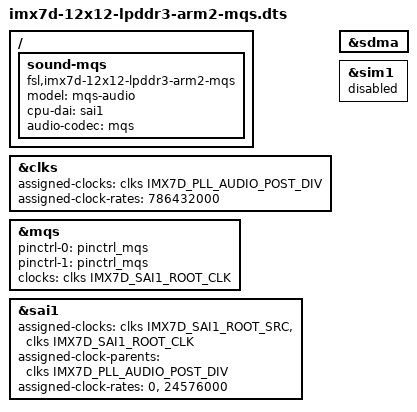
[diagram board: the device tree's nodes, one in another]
/*
 * Copyright (C) 2015 Freescale Semiconductor, Inc.
 *
 * This program is free software; you can redistribute it and/or modify
 * it under the terms of the GNU General Public License version 2 as
 * published by the Free Software Foundation.
 */

#include "imx7d-12x12-lpddr3-arm2.dts"

/ {
	sound-mqs {
		compatible = "fsl,imx7d-12x12-lpddr3-arm2-mqs",
				"fsl,imx-audio-mqs";
		model = "mqs-audio";
		cpu-dai = <&sai1>;
		audio-codec = <&mqs>;
	};
};

&clks {
	assigned-clocks = <&clks IMX7D_PLL_AUDIO_POST_DIV>;
	assigned-clock-rates = <786432000>;
};

&mqs {
	pinctrl-names = "default", "sleep";
	pinctrl-0 = <&pinctrl_mqs>;
	pinctrl-1 = <&pinctrl_mqs>;
	clocks = <&clks IMX7D_SAI1_ROOT_CLK>;
	clock-names = "mclk";
	status = "okay";
};

&sai1 {
	assigned-clocks = <&clks IMX7D_SAI1_ROOT_SRC>,
			  <&clks IMX7D_SAI1_ROOT_CLK>;
	assigned-clock-parents = <&clks IMX7D_PLL_AUDIO_POST_DIV>;
	assigned-clock-rates = <0>, <24576000>;
	status = "okay";
};

&sdma {
	status = "okay";
};

&sim1 {
	status = "disabled";
};
